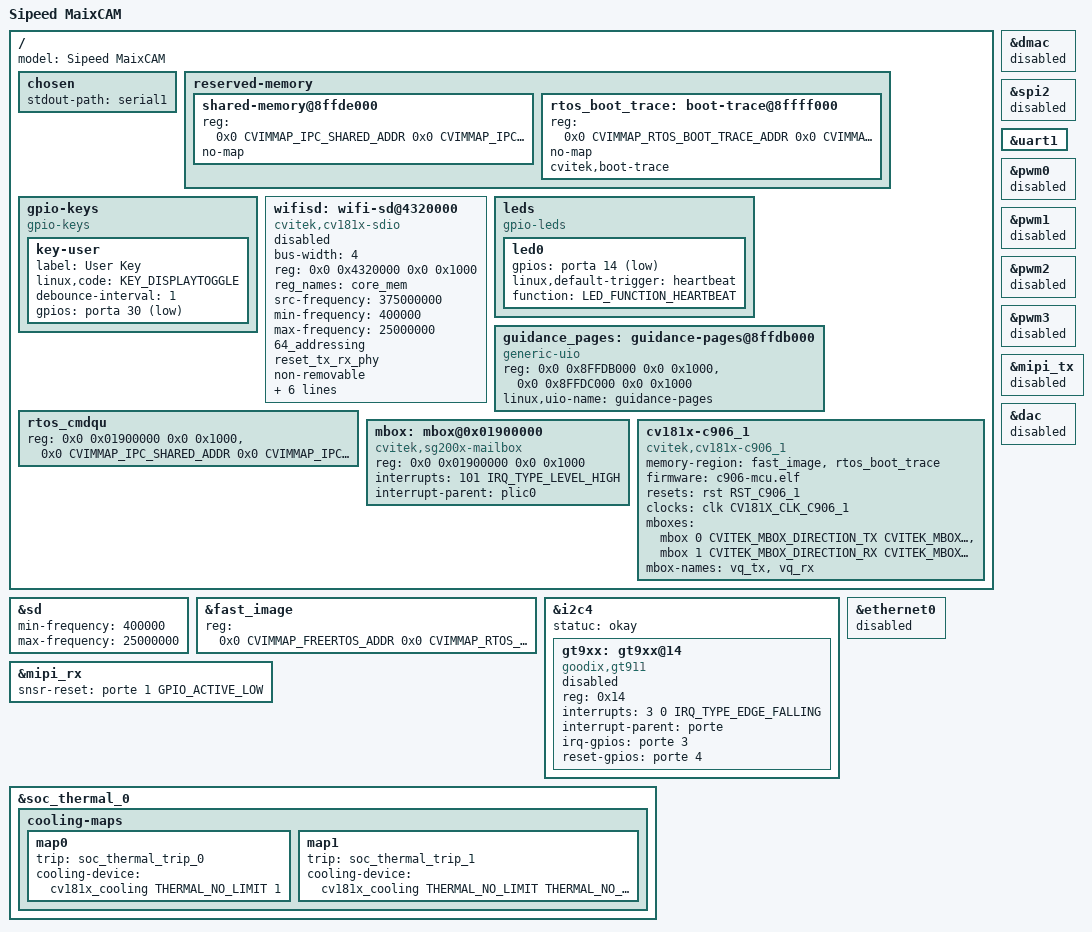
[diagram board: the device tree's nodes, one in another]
/dts-v1/;
#include "cv181x_base_riscv.dtsi"
#include "cv181x_asic_qfn.dtsi"
#include "cv181x_asic_sd.dtsi"
#include "cv181x_default_memmap.dtsi"

#include <dt-bindings/input/linux-event-codes.h>
#include <dt-bindings/gpio/gpio.h>
#include <dt-bindings/leds/common.h>
#ifndef __UBOOT__
#include <dt-bindings/mailbox/cvitek-mailbox.h>
#endif

&sd {
        min-frequency = <400000>; // 400Khz
        //max-frequency = <50000000>; // 50Mhz
        max-frequency = <25000000>; // 25Mhz
        //max-frequency = <10000000>; // 10Mhz
        //max-frequency = <5000000>; // 5Mhz
};

&fast_image {
	reg = <0x0 CVIMMAP_FREERTOS_ADDR 0x0 CVIMMAP_RTOS_FIRMWARE_SIZE>;
};

&dmac {
	/*
	 * 这颗 DesignWare AXI DMAC 的通道分区是存在的（固件侧 sg200x_dma.hpp：
	 * OWNED_CHANNEL_MASK = 0xF0，注释写明 0–3 归 Linux、4–7 归 C906L），但它现在
	 * **不能**交给 Linux：实测把节点打开（哪怕 dma-channels = 4）后，内核在 DMAC
	 * probe 处停住——串口停在 7.4 秒、无 panic、USB 消失，正是"总线被挂住"的签名。
	 * probe 会去开关 clk_sdma_axi 并写控制器全局寄存器，而固件和启动器已经在用它。
	 *
	 * 相机不受影响：drivers/media/platform/cvitek 的 CIF 驱动不走 dmaengine，
	 * 它不需要这个设备节点。
	 *
	 * 所以：控制器整体归 C906L。若将来确实要让 Linux 用这条 DMA，先把 probe 为什么会
	 * 挂查清楚，再把 dma-channels 设成 8 − popcount(0xF0) = 4（validate.py 检查这个数），
	 * 并且只能碰 0–3 通道。
	 * The controller is the C906L's.  Enabling the node here hung the board inside the
	 * driver's probe (serial stopped at 7.4 s, no panic, USB gone) -- a bus that never
	 * answers, because probe touches the shared clock and global registers.  The camera
	 * does not need it: the CIF driver has its own DMA and never asks dmaengine.
	 */
	status = "disabled";
};


/*
 * SPI2 is the IMU bus on the C906L side.  It has no Linux client on this board, so
 * leaving it enabled only lets dw-apb-ssi probe the controller and take its reset and
 * clock away from the remote core.  Declaring it disabled gives each controller one
 * owner; the C906L firmware configures it unconditionally at bring-up.
 */
&spi2 {
	status = "disabled";
};

/delete-node/ &vdev0vring0;
/delete-node/ &vdev0vring1;
/delete-node/ &vdev0buffer;


&uart1 {
        status = "okay";
};

/*
 * 控制台跟着 UART1 走：UART1 的两个焊盘就是 JTAG 的 TDI/TDO（IIC0_SCL/SDA，见板级
 * cvi_board_init 把 0x03001070/74 写成 func 1），UART0 的两个焊盘归 C906L 的 PWM4/5。
 * OpenSBI 用的就是这张 DT（`FW_FDT_PATH=u-boot.dtb`），继承来的 stdout-path="serial0"
 * 会让它在 U-Boot 之前把字打到归固件的那两个脚上，所以这里要覆盖它。内核另由 cmdline
 * 的 console=ttyS1 指定，两者必须指向同一个口（validate.py 查这个）。
 * The console follows UART1, whose pads are the JTAG TDI/TDO pair (IIC0_SCL/SDA; the
 * board's cvi_board_init muxes 0x03001070/74 to func 1).  UART0's pads belong to the
 * C906L's PWM4/5.  OpenSBI consumes this same DT as its FW_FDT, so the inherited
 * stdout-path="serial0" would make it print on the firmware's pads before U-Boot runs;
 * override it here.  The kernel's console=ttyS1 in the cmdline must name the same port.
 */
/ {
	chosen {
		stdout-path = "serial1";
	};
};

/*
 * 四个 PWM 控制器全归 C906L。这块板子上 Linux 没有任何 PWM 消费者（背光、风扇、
 * 触摸屏都已经 disabled），而固件在四个控制器上都用到通道：
 *   pwm0 → 舵面 PWM1/2（`GPIO_RTX`/`GPIO_ZQ`）
 *   pwm1 → 舵面 PWM4/5（`UART0_TX`/`UART0_RX`，控制台已经搬到 UART1）
 *   pwm2 → 加热 PWM10
 *   pwm3 → 屏幕 PWM14/15
 * 让内核 probe 这些控制器只会带来两件事：把共享的 `CV181X_CLK_PWM` 门当成自己的，
 * 以及往固件正在用的寄存器里写。所以一个都不留给它。
 *
 * All four PWM controllers belong to the C906L.  Linux has no PWM consumer on this
 * board (backlight, fan and touchscreen are all disabled), while the firmware uses
 * channels in every controller: pwm0 for surfaces PWM1/2, pwm1 for PWM4/5 (the console
 * has moved to UART1, so the UART0 pads are free), pwm2 for the heater PWM10, and pwm3
 * for the screen's PWM14/15.  Letting the kernel probe them only claims the shared
 * `CV181X_CLK_PWM` gate and writes registers the firmware is using.
 */
&pwm0 {
	status = "disabled";
};

&pwm1 {
	status = "disabled";
};

&pwm2 {
	status = "disabled";
};

&pwm3 {
	status = "disabled";
};

&mipi_tx {
	status = "disabled";
};

&i2c4 {
        statuc = "okay";
        gt9xx: gt9xx@14 {
                compatible = "goodix,gt911";
                reg = <0x14>;
		interrupts = <3 0 IRQ_TYPE_EDGE_FALLING>;
		interrupt-parent = <&porte>;
                irq-gpios= <&porte 3 0>;
                reset-gpios = <&porte 4 0>;
                status = "disabled";
        };
};


&dac {
        status = "disabled";
        /delete-property/ mute-gpio-r;
};

&ethernet0 {
	status = "disabled";
};

&mipi_rx {
        snsr-reset = <&porte 1 GPIO_ACTIVE_LOW>;
};

&soc_thermal_0 {
	cooling-maps {
		map0 {
			trip = <&soc_thermal_trip_0>;
			cooling-device = <&cv181x_cooling THERMAL_NO_LIMIT 1>;
		};
		map1 {
			trip = <&soc_thermal_trip_1>;
			cooling-device = <&cv181x_cooling THERMAL_NO_LIMIT THERMAL_NO_LIMIT>;
		};
	};
};

/ {
        model = "Sipeed MaixCAM";

	reserved-memory {
		/* 命令队列窗口：与 rtos_cmdqu 的 shared-memory 资源是同一段，必须独立 no-map。
		 * The command-queue window: the same band as rtos_cmdqu's shared-memory
		 * resource, and it has to stay its own no-map reservation. */
		shared-memory@8ffde000 {
			reg = <0x0 CVIMMAP_IPC_SHARED_ADDR 0x0 CVIMMAP_IPC_SHARED_SIZE>;
			no-map;
		};

		/* 固件区之上是命令队列窗口，再往上是这一页；三者首尾相接，共 2 MiB。
		 * The firmware band, then the command-queue window, then this page: three
		 * touching reservations that add up to the whole 2 MiB. */
		rtos_boot_trace: boot-trace@8ffff000 {
			reg = <0x0 CVIMMAP_RTOS_BOOT_TRACE_ADDR 0x0 CVIMMAP_RTOS_BOOT_TRACE_SIZE>;
			no-map;
			cvitek,boot-trace;
		};
	};

	/delete-node/ saradc;
	/delete-node/ rtc;

	/delete-node/ wifi_pin;
	/delete-node/ bt_pin;
	/delete-node/ sound_adc;
	/delete-node/ sound_dac;
	/delete-node/ sound_PDM;

        gpio-keys {
                compatible = "gpio-keys";
                key-user {
                        label = "User Key";
                        linux,code = <KEY_DISPLAYTOGGLE>;
                        debounce-interval = <1>;
                        gpios = <&porta 30 1>;
                };
        };

        wifisd:wifi-sd@4320000 {
                compatible = "cvitek,cv181x-sdio";
                bus-width = <4>;
                reg = <0x0 0x4320000 0x0 0x1000>;
                reg_names = "core_mem";
                src-frequency = <375000000>;
                min-frequency = <400000>; // 400Khz
                //max-frequency = <50000000>; // 50Mhz
                //max-frequency = <45000000>; // 45Mhz
                //max-frequency = <40000000>; // 40Mhz
                //max-frequency = <35000000>; // 35Mhz
                //max-frequency = <30000000>; // 30Mhz
                max-frequency = <25000000>; // 25Mhz
                //max-frequency = <20000000>; // 20Mhz
                //max-frequency = <15000000>; // 15Mhz
                //max-frequency = <10000000>; // 10Mhz
                //max-frequency = <5000000>; // 5Mhz
                64_addressing;
                reset_tx_rx_phy;
                non-removable;
                pll_index = <0x7>;
                pll_reg = <0x300207C>;
                no-mmc;
                no-sd;
                /*
                 * SDIO1 is reserved for the external ESP32-C5 slave in the
                 * C906 bring-up image.  Leaving the in-tree cvi host enabled
                 * makes Linux probe the same controller and race the C906
                 * remote processor (and this kernel's sdhci_cvi_remove has a
                 * NULL-pointer bug when detached at runtime).  Keep the node
                 * present for board variants that explicitly re-enable it,
                 * but do not bind the Linux driver by default.
                 */
                status = "disabled";
                interrupts = <38 IRQ_TYPE_LEVEL_HIGH>;
                interrupt-parent = <&plic0>;
        };

        leds {
        	compatible = "gpio-leds";
	        led0 {
		        gpios = <&porta 14 GPIO_ACTIVE_LOW>;
		        linux,default-trigger = "heartbeat";
		        function = LED_FUNCTION_HEARTBEAT;
	        };
        };
#ifndef __UBOOT__        
	/*
	 * The two 4 KiB pages the C906L firmware shares with Linux: console (index 0)
	 * and shared page (index 1).  They sit inside fast_image, which already
	 * reserves the range, so this node reserves nothing -- it gives userspace a
	 * mapping through UIO and a stable name.
	 * No interrupts: mailbox IRQ 101 belongs to cv181x_rtos_cmdqu alone, and the
	 * firmware notification rides its RTOS_CMDQU_WAIT_EVENT ioctl.
	 * 两个 4 KiB 页（console = map 0，共享页 = map 1）：它们落在 fast_image 里，
	 * 这里只提供 UIO 映射和一个稳定的名字。不带中断：mailbox 的 IRQ 101 归
	 * cv181x_rtos_cmdqu 独占，固件通知走它的 RTOS_CMDQU_WAIT_EVENT。
	 */
	guidance_pages: guidance-pages@8ffdb000 {
		compatible = "generic-uio";
		reg = <0x0 0x8FFDB000 0x0 0x1000>,
		      <0x0 0x8FFDC000 0x0 0x1000>;
		reg-names = "console", "shared";
		linux,uio-name = "guidance-pages";
	};

	rtos_cmdqu {
		/* mailbox MMIO 页 + 命令队列窗口。第二段不是相机环：它是 cmdqu 的数据区，
		 * 去掉它这块板子就起不来（实测）。The mailbox page plus the command-queue
		 * window; the second entry is cmdqu's data area, not the retired camera
		 * ring -- dropping it stops the board from booting. */
		reg = <0x0 0x01900000 0x0 0x1000>,
		      <0x0 CVIMMAP_IPC_SHARED_ADDR 0x0 CVIMMAP_IPC_SHARED_SIZE>;
		reg-names = "mailbox", "shared-memory";
	};

        mbox: mbox@0x01900000 {
                compatible = "cvitek,sg200x-mailbox";
		reg = <0x0 0x01900000 0x0 0x1000>;
		reg-names = "mailbox";
                interrupts	= <101 IRQ_TYPE_LEVEL_HIGH>;
                interrupt-parent = <&plic0>;
                status = "okay";
                #mbox-cells = <4>;
        };

        cv181x-c906_1 {
		compatible	= "cvitek,cv181x-c906_1";
		/* The mailbox-only firmware has no RPMsg resource table. */
		memory-region	= <&fast_image &rtos_boot_trace>;
                firmware        = "c906-mcu.elf";
                resets		= <&rst RST_C906_1>;
		reset-names	= "sw_reset";
                clocks		= <&clk CV181X_CLK_C906_1>;
                clock-names     = "clk_c906_1";
                mboxes		= <&mbox 0 CVITEK_MBOX_DIRECTION_TX CVITEK_MBOX_C906_1 1>, <&mbox 1 CVITEK_MBOX_DIRECTION_RX CVITEK_MBOX_C906_1 1>;
	        mbox-names	= "vq_tx", "vq_rx";
                status		= "okay";
	};
#endif
};
